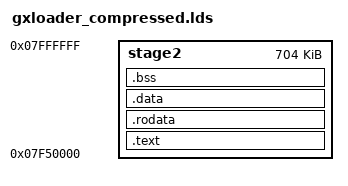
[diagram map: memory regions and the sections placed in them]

#include "version_autogenerated.h"

#define ZIMAGE_MAGIC(x) (x)

MEMORY
{
	stage2	:	ORIGIN = 0x07f50000,       	LENGTH = 0xb0000
}

ENTRY(decompress_entry)
SECTIONS {
	. = ALIGN(2048);
	.text :
	{
		_stage2_start_ = .;
		_stage2_text_start_ = .;
		cpu/compressed/start.o(.text*)
		cpu/compressed/start.o(.rodata*)
		cpu/compressed/start.o(.data*)
		*(.cache_section)
		*(.sram_text)
		*(.irq_text)
		. = ALIGN(512);
		*(.fiq_text)
		. = ALIGN(512);
		*(.entry_text)
		. = ALIGN(4);
		*(.text*)
		. = ALIGN(4);
		_stage2_text_end_ = .;
		__commands_begin = .;
		KEEP(*(.data.commands))
		. = ALIGN(4);
		__commands_end = .;
	} > stage2

	.rodata : { *(SORT_BY_ALIGNMENT(SORT_BY_NAME(.rodata*))) } > stage2

	. = ALIGN(2048);
	.data :
	{
		_stage2_data_start_ = .;
		*(.data*)
		. = ALIGN(16);
		_stage2_data_end_ = .;
	} > stage2

	 _magic_sig = ZIMAGE_MAGIC(0x016f2818);
	 _magic_start = ZIMAGE_MAGIC(_stage2_start_);
	 _magic_end = ZIMAGE_MAGIC(_stage2_data_end_);

	. = ALIGN(4);
	.bss :
	{
		. = ALIGN(4);
		__bss_start__ = .;
		*(.bss*)
		*(COMMON)
		. = ALIGN(4);
		__bss_end__ = .;
	} > stage2

}

